# myir register map
Vendor: overlord; File version: 0.0.0
CPU: CA53 r0p0, little endian, no MPU, FPU, I-cache, D-cache, 0 interrupt priority bits
Registers are 32-bit, read-write, reset 0x0 unless marked. A register's access mark holds for its fields unless they carry their own. Offsets are from the block's base; [hi:lo] are bit positions; {n}, {i} and the like mark numbered series; 'fields as' and 'values as' point back to an identical list.

## SD0 — SDIO 0 Controller
Base 0xFF160000
Same registers: SD1 0xFF170000
0x00 REG_SDMASYSADDRLO 16-bit — Dual purpose: low SDMA address, Auto CMD23 arg.
  [15:0] SDMA_SYSADDRESS
0x02 REG_SDMASYSADDRHI 16-bit — Dual purpose: high SDMA address, Auto CMD23 arg.
  [15:0] SDMA_SYSADDRESS
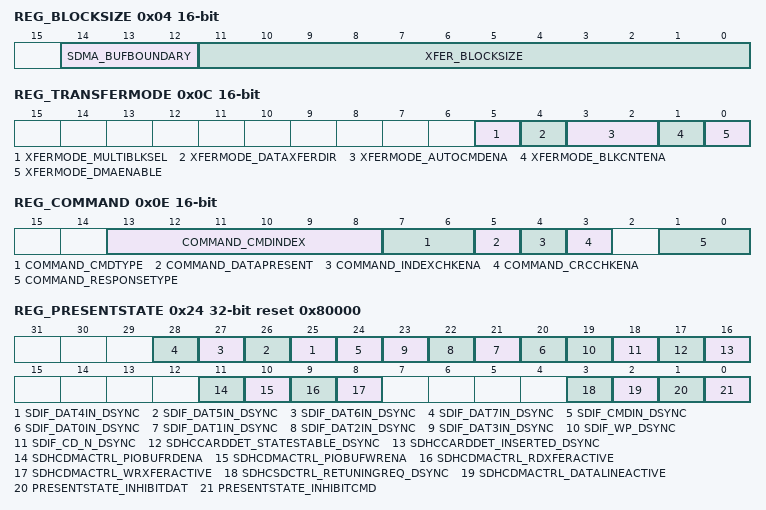
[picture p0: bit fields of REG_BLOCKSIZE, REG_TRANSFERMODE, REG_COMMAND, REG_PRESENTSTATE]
0x04 REG_BLOCKSIZE 16-bit — Configure the Number of Bytes in a Data Block.
  [14:12] SDMA_BUFBOUNDARY — The System Address register is updated at every system boundary during the DMA transfer The DMA transfer waits at the every boundary specified by these fields and the SDIO controller generates the DMA interrupt to request the controller to update the System Address register. This function is active when the [DMA Enable] bit in the Transfer Mode register is set = 1. 000b: 4KB 001b: 8KB 010b: 16KB 011b: 32KB 100b: 64KB 101b: 128KB 110b: 256KB 111b: 512KB
  [11:0] XFER_BLOCKSIZE — Read-only. Valid if no transaction is executing (i.e after a transaction has stopped). 0000h: No data transfer. 0001h: 1 byte 0002h: 2 bytes 0003h: 3 bytes .. 0200h: 512 bytes .. 0800h: 2048 bytes (maximum block size)
0x06 REG_BLOCKCOUNT 16-bit — Configure the number of data blocks
  [15:0] XFER_BLOCKCOUNT — The controller decrements the block count after each block transfer and stops transfers when the count reaches zero. 0000h: 0 blocks, transfers stop. 0001h: 1 block. 0002h: 2 blocks. .. FFFFh: 65535 blocks. This register is enabled when Block Count Enable in the Transfer Mode register is set to 1 and is valid only for multi-block transfers. Accessed the register when no transactions are executing (i.e., after a transaction has stopped). During a transfer, reads return an invalid value and writes are ignored. When saving transfer context as a result of Suspend command, the number of blocks yet to be transferred can be determined by reading this register. When restoring transfer context prior to issuing a Resume command, the Host Driver shall restore the previously save block count.
0x08 REG_ARGUMENT1LO 16-bit — Lower bits of SD Command Argument
  [15:0] COMMAND_ARGUMENT1
0x0A REG_ARGUMENT1HI 16-bit — Upper bits of SD Command Argument
  [15:0] COMMAND_ARGUMENT1
0x0C REG_TRANSFERMODE 16-bit — Control the Data Transfer Operations.
  [5] XFERMODE_MULTIBLKSEL — '0' Single Block.'1' Multiple Block.
  [4] XFERMODE_DATAXFERDIR — 0: Write from Host to Card. 1: Read from Card to Host.
  [3:2] XFERMODE_AUTOCMDENA — 00: Auto Command Disabled. 01: Auto CMD12 Enabled. 10: Auto CMD23 Enabled. 11: reserved. There are two methods to stop multiple-block read and write operation. (1) Auto CMD12 Enable: Multiple-block read and write commands for memory require CMD12 to stop the operation. The controller issues CMD12 automatically when the last block transfer is completed. Auto CMD12 error is indicated in the Auto CMD Error Status register. The driver shall not set this bit if the command does not require Auto CMD12. (2) Auto CMD23 Enable: The controller issues an Auto CMD23 before issuing a command specified in the Command Register. The following conditions are required to use the Auto CMD23. * Auto CMD23 Supported (Host Controller Version is 3.00 or later). * A memory card that supports CMD23 (SCR[33]=1). * If DMA is used, it shall be ADMA. * Only when CMD18 or CMD25 is issued. By writing the Command register, the controller issues a CMD23 first and then issues a command specified by the Command Index in Command register 32-bit block count value for CMD23 is set to SDMA System Address / Argument 2 register.
  [1] XFERMODE_BLKCNTENA — 0: disable (setting is also useful for executing an infinite transfer). 1: enable. Applicable to multiple block transfers.
  [0] XFERMODE_DMAENABLE — If this bit is set to 1, a DMA operation shall begin when the Host Driver writes to the upper byte of Command register (00Fh). 0: disable DMA. 1: enable DMA.
0x0E REG_COMMAND 16-bit — Controller Commands.
  [13:8] COMMAND_CMDINDEX — * ACMD [0:63].
  [7:6] COMMAND_CMDTYPE — Suspend Command: If the Suspend command succeeds, the controller assumes the SD I/O has been released and that it is possible to issue the next command using the SD_DAT signals. The controller de-asserts Read Wait for read transactions and stops checking busy for write transactions. The Interrupt cycle starts in 4-bit mode. If the Suspend command fails, the controller maintain its current state. and the controller shall restart the transfer by setting Continue Request in the Block Gap Control Register. Resume Command: The SDIO controller re-starts the data transfer by restoring the registers in the range of 000-00Dh. The controller checks for busy before starting write transfers. Abort Command: * If this command is set when executing a read transfer, the controller stops adding content to the receive buffer. * If this command is set when executing a write transfer, the controller stops driving the SD_DAT signals. After issuing the Abort command, the controller should issue a software reset. 00: Normal 01: Suspend 10: Resume 11: Abort
  [5] COMMAND_DATAPRESENT — If is set to 0 for the following: 1. Commands using only CMD line (ex. CMD52). 2. Commands with no data transferbut using busy signal on DAT[0]line (R1b or R5b ex. CMD38). 3. Resume Command.'0' Data not Present'1' Data present
  [4] COMMAND_INDEXCHKENA — If it is not, it is reported as a Command Index Error. If this bit is set to 0, the Index field is not checked.'0' Disable'1' Enable
  [3] COMMAND_CRCCHKENA — If an error is detected, it is reported as a Command CRC Error. If this bit is set to 0, the CRC field is not checked.'0' Disable'1' Enable
  [1:0] COMMAND_RESPONSETYPE — '00' No Response'01' Response Length 136'10' Response Length 48'11' Response Length 48 check busy after response
0x10 REG_RESPONSE0 16-bit — Response 0 from SD Card.
  [15:0] COMMAND_RESPONSE
{0x10+2i} REG_RESPONSE{i} 16-bit (i=1..7) — This register is used to store responses from SD Cards
  [15:0] COMMAND_RESPONSE
0x20 REG_DATAPORT — Read/write internal buffer.
  [31:0] SDHCDMACTRL_PIOBUFRDDATA
0x24 REG_PRESENTSTATE reset 0x80000 — SDIO Controller Status, read-only.
  [n+21] SDIF_DAT{n}IN_DSYNC (n=4..7)
  [24] SDIF_CMDIN_DSYNC
  [n+20] SDIF_DAT{n}IN_DSYNC (n=0..3) — This is especially useful in detecting the busy signal level from DAT[0].
  [19] SDIF_WP_DSYNC — This bit reflects the inversion of the SDx_WP pin. 0: Write protected, SDx_WP pin = High. 1: Write enabled, SDx_WP pin = Low.
  [18] SDIF_CD_N_DSYNC — 0: No Card present, SDx_CDn pin = High. 1: Card present, SDx_CDn pin = Low.
  [17] SDHCCARDDET_STATESTABLE_DSYNC — If it is 0, the Card Detect Pin Level is not stable. If this bit is set to 1,it means the Card Detect Pin Level is stable. The Software Reset For All in the Software Reset Register shall not affect this bit.'0' Reset of Debouncing'1' No Card or Inserted
  [16] SDHCCARDDET_INSERTED_DSYNC — Read-only. Changing from 0 to 1 generates a Card Insertion interrupt in the Normal Interrupt Status register. Changing from 1 to 0 generates a Card Removal interrupt in the Normal Interrupt Status register. The Software Reset For All in the Software Reset register does not affect this bit. If a Card is removed while its power is on and its clock is oscillating, the controller clears SD Bus Power in the Power Control register and SD Clock Enable in the Clock control register. In addition the Host Driver should clear the controller using the Software Reset For All in Software register. The card detect is active regardless of the SD Bus Power. 0: Reset or Debouncing or No Card. 1: Card Inserted.
  [11] SDHCDMACTRL_PIOBUFRDENA — This read only flag indicates that valid data exists in the host side buffer status. If this bit is 1, readable data exists in the buffer. A change of this bit from 1 to 0 occurs when all the block data is read from the buffer. A change of this bit from 0 to 1 occurs when all the block data is ready in the buffer and generates the Buffer Read Ready Interrupt.'0' Read Disable'1' Read Enable
  [10] SDHCDMACTRL_PIOBUFWRENA — Read-only. This flag indicates if space is available for writing data. 0: do not write to the register port. 1: data can be written to the buffer via the register port. A change from 1 to 0 indicates the buffer is full. A change from 0 to 1 occurs when top of block data can be written to the buffer and generates the Buffer Write Ready Interrupt.
  [9] SDHCDMACTRL_RDXFERACTIVE — Read-only. This bit is set to 1 for either of the following conditions: * After the end bit of the read command, or * When writing a 1 to continue Request in the Block Gap Control register to restart a read transfer. This bit is cleared to 0 for either of the following conditions: * When the last data block as specified by block length is transferred to the system, or * When all valid data blocks have been transferred to the system and no current block transfers are being sent as a result of the Stop At Block Gap Request set to 1. A transfer complete interrupt is generated when this bit changes to 0. 0: No valid data 1: Transferring data
  [8] SDHCDMACTRL_WRXFERACTIVE — If this bit is 0, it means no valid write data exists in the HC. This bit is set in either of the following cases: * After the end bit of the write command. * When writing a 1 to Continue Request in the Block Gap Control register to restart a write transfer. This bit is cleared in either of the following cases: * After getting the CRC status of the last data block as specified by the transfer count (Single or Multiple) * After getting a CRC status of any block where data transmission is about to be stopped by a Stop At Block Gap Request. During a write transaction, a Block Gap Event interrupt is generated when this bit is changed to 0, as a result of the Stop At Block Gap Request being set. This status is useful for the HD in determining when to issue commands during write busy.'0' No valid data'1' Transferring data
  [3] SDHCSDCTRL_RETUNINGREQ_DSYNC — Re-tune the I/O timing when the data window is shifted by temperature changes or to improve timing margins to receive correct data. 0: Sampling clock is okay (it's fixed timing or well tuned). 1: Re-tune the sampling clock. This bit is set = 0 when a command is issued by setting the Execute Tuning bit in the Host Control 2 register. When software writes this bit from a 0 to 1 and [Sampling Clock Select] = 1 (not fixed sampling), the controller triggers the re-tune event. Refer to Normal Interrupt registers for more detail.
  [2] SDHCDMACTRL_DATALINEACTIVE — 1: active.
  [1] PRESENTSTATE_INHIBITDAT — [ ] 0: controller can issue the next SD command. Commands with busy signal belong to Command Inhibit (DAT) (ex. R1b, R5b type). When the status indicator changes from a 0 to 1, the Transfer Complete interrupt asserts. Note: The SD Host Driver can save registers in the range of 000-00Dh; for a suspend transaction this bit changes from 1 to 0.'0' Can issue command which uses the DAT line'1' Cannot issue command which uses the DATline
  [0] PRESENTSTATE_INHIBITCMD — 0: The CMD line is not in use and the controller can issue a SD command using the CMD line. This bit is set immediately after the Command register (00Fh) is written. This bit is cleared when the command response is received. Even if the Command Inhibit (DAT) is set to 1, Commands using only the CMD line can be issued if this bit is 0. Changing from 1 to 0 generates a Command complete interrupt in the Normal Interrupt Status register. If the controller cannot issue the command because of a command conflict error or because of Command Not Issued By Auto CMD12 Error, this bit remains a 1 and the Command Complete interrupt is not set. Status issuing Auto CMD12 is not read from this bit. Auto CMD12 and Auto CMD23 consist of two responses. In this case, this bit is not cleared by the response of CMD12 or CMD23 but cleared by the response of a read/write command. Status issuing Auto CMD12 is not read from this bit. So if a command is issued during Auto CMD12 operation, controller issues two commands: CMD12 and a command set by Command register.
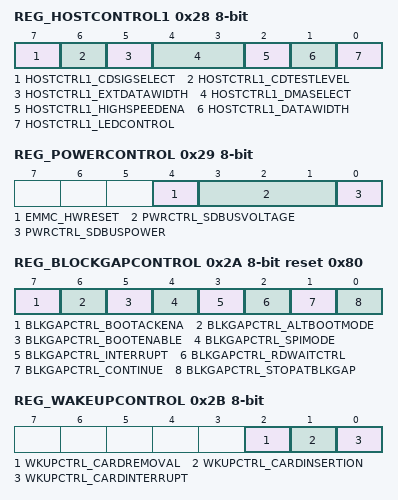
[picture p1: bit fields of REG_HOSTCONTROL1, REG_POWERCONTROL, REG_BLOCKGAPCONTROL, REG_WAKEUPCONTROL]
0x28 REG_HOSTCONTROL1 8-bit — Controller Configuration.
  [7] HOSTCTRL1_CDSIGSELECT — 0: SD_CDn is selected (for normal use) 1: The card detect test level is selected
  [6] HOSTCTRL1_CDTESTLEVEL — Generates (card ins or card removal) interrupt when the normal int sts enable bit is set.'0' No Card'1' Card Inserted
  [5] HOSTCTRL1_EXTDATAWIDTH — Support of this function is indicated in 8-bit Support for Embedded Device in the Capabilities register. If a device supports 8-bit bus mode, this bit may be set to 1. If this bit is 0, bus width is controlled by Data Transfer Width in the Host Control 1 register.This bit is not effective when multiple devices are installed on a bus slot (Slot Type is set to 10b in the Capabilities register). In this case, each device bus width is controlled by Bus Width Preset field in the Shared Bus register.'0' Bus width is selected by data transfer width'1' 8-bit bus width
  [4:3] HOSTCTRL1_DMASELECT — The host driver shall check support of DMA modes by referring the Capabilities register.'00' SDMA'01' 32 bit ADMA1 address'10' 32 bit ADMA2 address'11' 64 bit ADMA2 Address Note: Switching between 32-bit and 64-bit operation will require a reset. Write the [swreset_for_cmd] bit of SDHC register reg_software to reset.
  [2] HOSTCTRL1_HIGHSPEEDENA — Before setting this bit, the driver shall check the High Speed Support in the capabilities register. If this bit is set to 0 (default), the HC outputs CMD line and DAT lines at the falling edge of the SD clock (up to 25 MHz/20MHz for MMC). If this bit is set to 1,the HC outputs CMD line and DAT lines at the rising edge of the SD clock (up to 50 MHz for SD/52MHz for MMC)/208Mhz (for SD3.0). If Preset Value Enable in the Host Control 2 register is set to 1, Host Driver needs to reset SD Clock Enable before changing this field to avoid generating clock glitches. After setting this field, the Host Driver sets SD Clock Enable again. 0: Normal Speed Mode. 1: High Speed Mode.
  [1] HOSTCTRL1_DATAWIDTH — The driver shall select it to match the data width of the SD card. 0: 1-bit mode 1: 4-bit mode
  [0] HOSTCTRL1_LEDCONTROL — If the software is going to issue multiple SD commands, this bit can be set during all transactions. It is not necessary to change for each transaction.'0' LED Off'1' LED On
0x29 REG_POWERCONTROL 8-bit — SD Bus Power and Voltage Level.
  [4] EMMC_HWRESET
  [3:1] PWRCTRL_SDBUSVOLTAGE — Before setting this register, the HD shall check the voltage support bits in the capabilities register. If an unsupported voltage is selected, the Host System shall not supply SD bus voltage.'000'- '100' Reserved'101' 1.8V(Typ.)'110' 3.0V(Typ.)'111' 3.3V(Flattop.)
  [0] PWRCTRL_SDBUSPOWER — If the HC detects the No Card State, this bit shall be cleared.'0' Power Off'1' Power On
0x2A REG_BLOCKGAPCONTROL 8-bit reset 0x80 — This register is used to program the block gap request, read wait control and interrupt at block gap
  [7] BLKGAPCTRL_BOOTACKENA — '0' Will not wait for boot ack from eMMC card,'1' Wait for boot ack from eMMC card
  [6] BLKGAPCTRL_ALTBOOTMODE — '0' To stop alternative boot mode access,'1' To start alternative boot mode access
  [5] BLKGAPCTRL_BOOTENABLE — '0' To stop boot code access,'1' To start boot code access
  [4] BLKGAPCTRL_SPIMODE — '0' SD Mode, '1' SPI Mode
  [3] BLKGAPCTRL_INTERRUPT — Setting to 1 enables interrupt detection at the block gap for a multiple block transfer. If the SD card cannot signal an interrupt during a multiple block transfer, this bit should be set to 0. When the HD detects an SD card insertion, it shall set this bit according to the CCCR of the SDIO card.
  [2] BLKGAPCTRL_RDWAITCTRL — If the card supports read wait, set this bit to enable use of the read wait protocol to stop read data using DAT[2] line. Otherwise the HC has to stop the SD clock to hold read data, which restricts commands generation. When the HD detects an SD card insertion, it shall set this bit according to the CCCR of the SDIO card. If the card does not support read wait, this bit shall never be set to 1 otherwise DAT line conflict may occur. If this bit is set to 0, Suspend / Resume cannot be supported.'0' Disable Read-Wait Control'1' Enable Read-Wait Control
  [1] BLKGAPCTRL_CONTINUE — To cancel stop at the block gap, set Stop At block Gap Request to 0 and set this bit to restart the transfer. The HC automatically clears this bit in either of the following cases: 1) In the case of a read transaction, the DAT Line Active changes from 0 to 1 as a read transaction restarts. 2) In the case of a write transaction, the Write transfer active changes from 0 to 1 as the write transaction restarts. Therefore it is not necessary for Host driver to set this bit to 0. If Stop At Block Gap Request is set to 1, any write to this bit is ignored.'0' Ignore'1' Restart
  [0] BLKGAPCTRL_STOPATBLKGAP — Applicable for non-DMA, SDMA, and ADMA transfers. Until the transfer complete is set to 1, indicating a transfer completion the Host Driver shall leave this bit set to 1. Clearing both the Stop At Block Gap Request and Continue Request shall not cause the transaction to restart. Read Wait is used to stop the read transaction at the block gap. The controller shall honour Stop At Block Gap Request for write transfers, but for read transfers it requires that the SD card support Read Wait. Therefore the Host Driver shall not set this bit during read transfers unless the SD card supports Read Wait and has set Read Wait Control to 1. In case of write transfers in which the HD writes data to the Buffer Data Port register, the HD shall set this bit after all block data is written. If this bit is set to 1, the HD shall not write data to Buffer data port register. This bit affects Read Transfer Active, Write Transfer Active, DAT line active and Command Inhibit (DAT) in the Present State register.'0' Transfer'1' Stop
0x2B REG_WAKEUPCONTROL 8-bit — Wakeup Functionality Control.
  [2] WKUPCTRL_CARDREMOVAL — FN_WUS (Wake up Support) in CIS does not affect this bit.'0' Disable'1' Enable
  [1] WKUPCTRL_CARDINSERTION — FN_WUS (Wake up Support) in CIS does not affect this bit.'0' Disable'1' Enable
  [0] WKUPCTRL_CARDINTERRUPT — This bit can be set to 1 if FN_WUS (Wake Up Support) in CIS is set to 1.'0' Disable'1' Enable
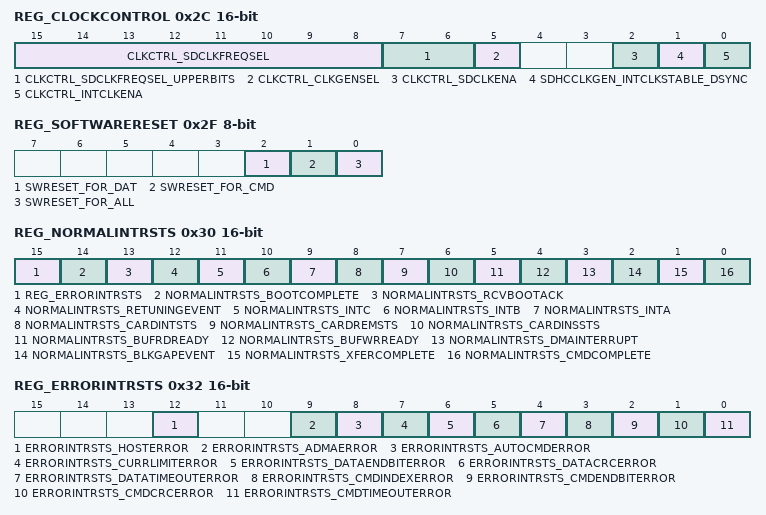
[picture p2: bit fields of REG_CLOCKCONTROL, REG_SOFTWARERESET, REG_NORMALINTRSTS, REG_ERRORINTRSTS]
0x2C REG_CLOCKCONTROL 16-bit — Clock Frequency Control and State.
  [15:8] CLKCTRL_SDCLKFREQSEL — The frequency is not programmed directly; rather this register holds the divisor of the Base Clock Frequency For SD clock in the capabilities register. Only the following settings are allowed. (1) 8-bit Divided Clock Mode 80h - base clock divided by 256 40h - base clock divided by 128 20h - base clock divided by 64 10h - base clock divided by 32 08h - base clock divided by 16 04h - base clock divided by 8 02h - base clock divided by 4 01h - base clock divided by 2 00h - base clock(10MHz-63MHz) Setting 00h specifies the highest frequency of the SD Clock. When setting multiple bits, the most significant bit is used as the divisor. But multiple bits should not be set. The two default divider values can be calculated by the frequency that is defined by the Base Clock Frequency For SD Clock in the Capabilities register. 1) 25 MHz divider value. 2) 400 KHz divider value. The frequency of the SDCLK is set by the following formula: Clock Frequency = (Baseclock) / divisor. Thus choose the smallest possible divisor which results in a clock frequency that is less than or equal to the target frequency. Maximum Frequency for SD = 50Mhz (base clock) Maximum Frequency for MMC = 52Mhz (base clock) Minimum Frequency = 195.3125Khz (50Mhz / 256), same calculation for MMC also. (2) 10-bit Divided Clock Mode Host Controller Version 3.00 supports this mandatory mode instead of the 8-bit Divided Clock Mode. The length of divider is extended to10 bits and all divider values shall be supported. 3FFh --1/2046 Divided Clock N -------1/2N Divided Clock (Duty 50%) 002h -- 1/4 Divided Clock 001h ---1/2 Divided Clock 000h --- Base Clock (10MHz-254MHz)
  [7:6] CLKCTRL_SDCLKFREQSEL_UPPERBITS
  [5] CLKCTRL_CLKGENSEL — If the Programmable Clock Mode is supported (non-zero value is set to Clock Multiplier in the Capabilities register), this bit attribute is RW, and if not supported, this bit attribute is RO and zero is read. This bit depends on the setting of Preset Value Enable in the Host Control 2 register. If the Preset Value Enable = 0, this bit is set by Host Driver. If the Preset Value Enable = 1, this bit is automatically set to a value specified in one of Preset Value registers.'0' Divided Clock Mode'1' Programmable Clock Mode
  [2] CLKCTRL_SDCLKENA — SDCLK frequency Select can be changed when this bit is 0. Then, the HC shall maintain the same clock frequency until SDCLK is stopped (Stop at SDCLK = 0). If the HC detects the No Card state, this bit shall be cleared.'0' Disable,'1' Enable
  [1] SDHCCLKGEN_INTCLKSTABLE_DSYNC — The SD Host Driver shall wait to set SD Clock Enable until this bit is set to 1. Note: This is useful when using PLL for a clock oscillator that requires setup time.'0' Not Ready,'1' Ready
  [0] CLKCTRL_INTCLKENA — The HC should stop its internal clock to go very low power state. Still, registers shall be able to be read and written. Clock starts to oscillate when this bit is set to 1. When clock oscillation is stable, the HC shall set Internal Clock Stable in this register to 1. This bit shall not affect card detection.'0' Stop,'1' Oscillate
0x2E REG_TIMEOUTCONTROL 8-bit — Set the Data Timeout Counter Value.
  [3:0] TIMEOUT_CTRVALUE — Refer to the Data Time-out Error in the Error Interrupt Status register for information on factors that dictate time-out generation. Time-out clock frequency will be generated by dividing the sdclockTMCLK by this value. When setting this register, prevent inadvertent time-out events by clearing the Data Time-out Error Status Enable (in the Error Interrupt Status Enable register). 1111 - Reserved 1110 - TMCLK * 2^27 -------------------- -------------------- 0001 - TMCLK * 2^14 0000 - TMCLK * 2^13
0x2F REG_SOFTWARERESET 8-bit — Software reset for data, command and all.
  [2] SWRESET_FOR_DAT — The following registers and bits are cleared by this bit: Buffer Data Port Register: Buffer is cleared and Initialized. Present State register: Buffer read Enable, Buffer write Enable, Read Transfer Active, Write Transfer Active, DAT Line Active, Command Inhibit (DAT). Block Gap Control register: Continue Request, Stop At Block Gap Request. Normal Interrupt Status register: Buffer Read Ready, Buffer Write Ready, Block Gap Event, Transfer Complete. 0: Operational. 1: Held in reset.
  [1] SWRESET_FOR_CMD — The following registers and bits are cleared by this bit: Present State register- Command Inhibit (CMD). Normal Interrupt Status register- Command Complete. 0: Operational. 1: Held in reset.
  [0] SWRESET_FOR_ALL — Register bits of type ROC, RW, RW1C, RWAC are cleared to 0. During its initialization, the HD shall set this bit to 1 to reset the HC. The HC shall reset this bit to 0 when capabilities registers are valid and the HD can read them. Additional use of Software Reset For All may not affect the value of the Capabilities registers. If this bit is set to 1, the SD card shall reset itself and must be re initialized by the HD. 0: Operational. 1: Held in reset.
0x30 REG_NORMALINTRSTS 16-bit — Status of all Interrupts
  [15] REG_ERRORINTRSTS — '0' No error'1' Error
  [14] NORMALINTRSTS_BOOTCOMPLETE — '0' Boot operation is not terminated'1' Boot operation is terminated
  [13] NORMALINTRSTS_RCVBOOTACK — '0' Boot ack not recieved'1' Boot ack is recieved
  [12] NORMALINTRSTS_RETUNINGEVENT — Host Controller requests Host Driver to perform re-tuning for next data transfer. Current data transfer (not large block count) can be completed without re-tuning.'0' Re-tuning not required'1' Re-tuning should be performed
  [11] NORMALINTRSTS_INTC — Writing this bit to 1 does not clear this bit. It is cleared by resetting the INT_C interrupt factor.
  [10] NORMALINTRSTS_INTB — Writing this bit to 1 does not clear this bit. It is cleared by resetting the INT_B interrupt factor.
  [9] NORMALINTRSTS_INTA — Writing this bit to 1 does not clear this bit. It is cleared by resetting the INT_A interrupt factor. NOTE: INT_A, INT_B, and INT_C are to be implemented based on the Application Requirements. By default these are not implemented as there is no specific requirement from Customers.
  [8] NORMALINTRSTS_CARDINTSTS — It is cleared by resetting the SD card interrupt factor. In 1-bit mode, the HC shall detect the Card Interrupt without SD Clock to support wakeup. In 4-bit mode, the card interrupt signal is sampled during the interrupt cycle, so there are some sample delays between the interrupt signal from the card and the interrupt to theHost system. when this status has been set and the HD needs to start this interrupt service, Card Interrupt Status Enable in the Normal Interrupt Status register shall be set to 0 in order to clear the card interrupt statuses latched in the HC and stop driving the Host System. After completion of the card interrupt service (the reset factor in the SD card and the interrupt signal may not be asserted), set Card Interrupt Status Enable to 1 and start sampling the interrupt signal again. Interrupt detected by DAT[1] is supported when there is a card per slot. In case of shared bus, interrupt pins are used to detect interrupts. If 000b is set to Interrupt Pin Select in the Shared Bus Control register, this status is effective. Non-zero value is set to Interrupt Pin Select, INT_A, INT_B or INT_C is then used to device interrupts. Card Interrupt: 0: inactive. 1: active.
  [7] NORMALINTRSTS_CARDREMSTS — When the HD writes this bit to 1 to clear this status the status of the Card Inserted in the Present State register should be confirmed. Because the card detect may possibly be changed when the HD clear this bit an Interrupt event may not be generated.'0' Card State Stable or Debouncing'1' Card Removed
  [6] NORMALINTRSTS_CARDINSSTS — When the HD writes this bit to 1 to clear this status the status of the Card Inserted in the Present State register should be confirmed. Because the card detect may possibly be changed when the HD clear this bit an Interrupt event may not be generated.'0' Card State Stable or Debouncing'1' Card Inserted
  [5] NORMALINTRSTS_BUFRDREADY — '0' Not ready to read buffer,'1' Ready to read buffer
  [4] NORMALINTRSTS_BUFWRREADY — '0' Not ready to write to buffer, '1' Ready to write to buffer
  [3] NORMALINTRSTS_DMAINTERRUPT — '0' No DMA Interrupt'1' DMA Interrupt is generated
  [2] NORMALINTRSTS_BLKGAPEVENT — Read Transaction: This bit is set at the falling edge of the DAT Line Active Status (When the transaction is stopped at SD Bus timing. The Read Wait must be supported inorder to use this function). Write Transaction: This bit is set at the falling edge of Write Transfer Active Status (After getting CRC status at SD Bus timing).'0' No Block Gap Event'1' Transaction stopped at Block Gap
  [1] NORMALINTRSTS_XFERCOMPLETE — Read Transaction: This bit is set at the falling edge of Read Transfer Active Status. There are two cases in which the Interrupt is generated. The first is when a data transfer is completed as specified by data length (After the last data has been read to the Host Sys- tem). The second is when data has stopped at the block gap and completed the data transfer by setting the Stop At Block Gap Request in the Block Gap Control Register (After valid data has been read to the Host System). Write Transaction: This bit is set at the falling edge of the DAT Line Active Status. There are two cases in which the Interrupt is generated. The first is when the last data is written to the card as specified by data length and Busy signal is released. The second is when data transfers are stopped at the block gap by setting Stop At Block Gap Request in the Block Gap Control Register and data transfers completed. (After valid data is written to the SD card and the busy signal is released). Note: Transfer Complete has higher priority than Data Time-out Error. If both bits are set to 1, the data transfer can be considered complete. Note: While performing tuning procedure (Execute Tuning is set to 1), Transfer Complete is not set to 1'0' No Data Transfer Complete,'1' Data Transfer Complete
  [0] NORMALINTRSTS_CMDCOMPLETE — If both are set to 1, it can be considered that the response was not received correctly.'0' No Command Complete,'1' Command Complete
0x32 REG_ERRORINTRSTS 16-bit — Error Interrupts Status
  [12] ERRORINTRSTS_HOSTERROR
  [9] ERRORINTRSTS_ADMAERROR — The state of the ADMA at an error occurrence is saved in the ADMA Error Status Register.'0' No error'1' Error
  [8] ERRORINTRSTS_AUTOCMDERROR — This bit is set when detecting that one of the bits D00-D04 in Auto CMD Error Status register has changed from 0 to 1. In case of Auto CMD12, this bit is set to 1, not only when the errors in Auto CMD12 occur but also when Auto CMD12 is not executed due to the previous command error.'0' No error'1' Error
  [7] ERRORINTRSTS_CURRLIMITERROR — If the HC supports the Current Limit Function, it can be protected from an Illegal card by stopping power supply to the card in which case this bit indicates a failure status. Reading 1 means the HC is not supplying power to SD card due to some failure. Reading 0 means that the HC is supplying power and no error has occurred. This bit shall always set to be 0, if the HC does not support this function.'0' No error'1' Power Fail Note: The current_Limit_Error is to be implemented if customer application requires it. By default it is not implemented as there is no specific requirement from Customers.
  [6] ERRORINTRSTS_DATAENDBITERROR
  [5] ERRORINTRSTS_DATACRCERROR — '0' No error'1' Error
  [4] ERRORINTRSTS_DATATIMEOUTERROR — Busy Timeout for R1b, R5b type. 2. Busy Timeout after Write CRC status 3. Write CRC status Timeout 4. Read Data Timeout.'0' No Error'1' Timeout
  [3] ERRORINTRSTS_CMDINDEXERROR — '0' No Error'1' Error
  [2] ERRORINTRSTS_CMDENDBITERROR — '0' No Error, '1' End bit error generated
  [1] ERRORINTRSTS_CMDCRCERROR — 1. If a response is returned and the Command Time-out Error is set to 0, this bit is set to 1 when detecting a CRT error in the command response 2. The HC detects a CMD line conflict by monitoring the CMD line when a command is issued. If the HC drives the CMD line to 1 level, but detects 0 level on the CMD line at the next SDCLK edge, then the HC shall abort the command (Stop driving CMD line) and set this bit to 1. The Command Timeout Error shall also be set to 1 to distinguish CMD line conflict.'0' No Error,'1' CRC Error
  [0] ERRORINTRSTS_CMDTIMEOUTERROR — If the HC detects a CMD line conflict, in which case Command CRC Error shall also be set. This bit shall be set without waiting for 64 SDCLK cycles because the command will be aborted by the HC.'0' Error'1' Timeout
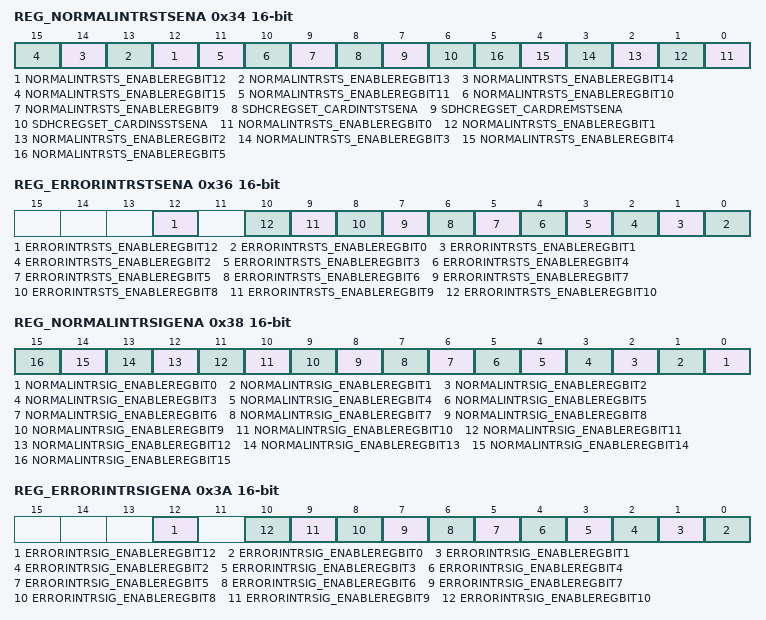
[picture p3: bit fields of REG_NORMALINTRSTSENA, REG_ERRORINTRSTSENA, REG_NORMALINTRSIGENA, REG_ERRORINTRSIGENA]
0x34 REG_NORMALINTRSTSENA 16-bit — Normal-type Interrupts Status Enables.
  [n] NORMALINTRSTS_ENABLEREGBIT{n} (n=12..15)
  [11] NORMALINTRSTS_ENABLEREGBIT11 — The Host Driver may clear this bit before servicing the INT_C and may set this bit again after all interrupt requests to INT_C pin are cleared to prevent inadvertent interrupts.
  [10] NORMALINTRSTS_ENABLEREGBIT10 — The Host Driver may clear this bit before servicing the INT_B and may set this bit again after all interrupt requests to INT_B pin are cleared to prevent inadvertent interrupts.
  [9] NORMALINTRSTS_ENABLEREGBIT9 — The Host Driver may clear this bit before servicing the INT_A and may set this bit again after all interrupt requests to INT_A pin are cleared to prevent inadvertent interrupts.
  [8] SDHCREGSET_CARDINTSTSENA — The Card Interruptdetection is stopped when this bit is cleared and restarted when this bit is set to 1. The HD may clear the Card Interrupt Status Enable before servicing the Card Interrupt and may set this bit again after all Interrupt requests from the card are cleared to prevent inadvertent Interrupts.
  [7] SDHCREGSET_CARDREMSTSENA
  [6] SDHCREGSET_CARDINSSTSENA
  [n] NORMALINTRSTS_ENABLEREGBIT{n} (n=0..5)
0x36 REG_ERRORINTRSTSENA 16-bit — Error-type Interrupts Status Enables.
  [12] ERRORINTRSTS_ENABLEREGBIT12, [n] ERRORINTRSTS_ENABLEREGBIT{n} (n=0..10)
0x38 REG_NORMALINTRSIGENA 16-bit — Normal-type Interrupts Signal Enables.
  [n] NORMALINTRSIG_ENABLEREGBIT{n} (n=0..15)
0x3A REG_ERRORINTRSIGENA 16-bit — Error-type Interrupts Signal Enables.
  [12] ERRORINTRSIG_ENABLEREGBIT12, [n] ERRORINTRSIG_ENABLEREGBIT{n} (n=0..10)
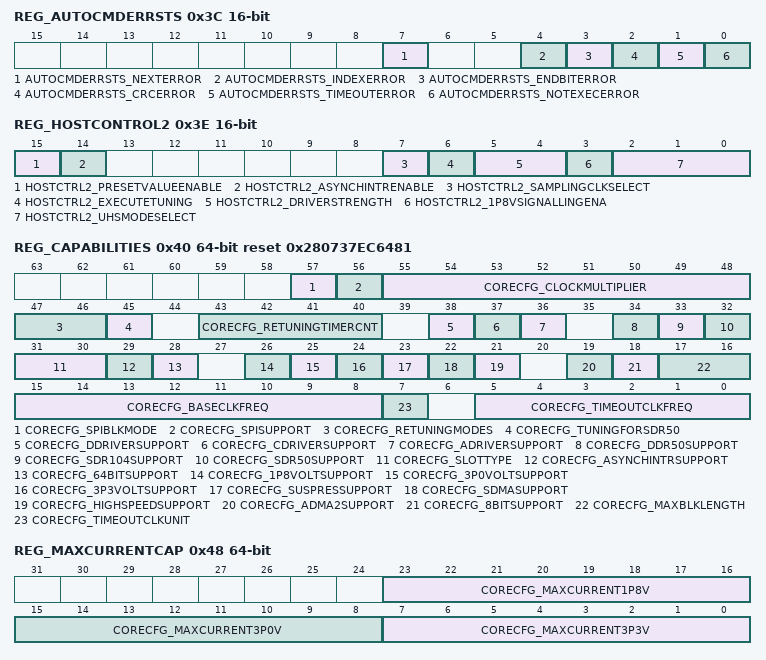
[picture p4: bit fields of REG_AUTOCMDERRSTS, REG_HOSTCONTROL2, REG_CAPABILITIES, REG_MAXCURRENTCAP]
0x3C REG_AUTOCMDERRSTS 16-bit — CMD12 response error of Auto CMD12 and CMD23.
  [7] AUTOCMDERRSTS_NEXTERROR — This bit is set to 0 when Auto CMD Error is generated by Auto CMD23.'0' No Error'1' Not Issued
  [4] AUTOCMDERRSTS_INDEXERROR — '0' No Error,'1' Error.
  [3] AUTOCMDERRSTS_ENDBITERROR — '0' No Error,'1' End Bit Error Generated
  [2] AUTOCMDERRSTS_CRCERROR — '0' No error'1' CRC Error Generated
  [1] AUTOCMDERRSTS_TIMEOUTERROR — If this bit is set to 1, the other error status bits (D04 - D02) are meaningless.'0' No error'1' Timeout
  [0] AUTOCMDERRSTS_NOTEXECERROR — Setting this bit to 1 means the HC cannot issue Auto CMD12 to stop memory multiple block transfer due to some error. If this bit is set to 1, other error status bits (D04 - D01) are meaningless. This bit is set to 0 when Auto CMD Error is generated by Auto CMD23'0' Executed, '1' Not Executed
0x3E REG_HOSTCONTROL2 16-bit — UHS Mode, I/O Drive, Tuning, Clocking, Intr, and Presets.
  [15] HOSTCTRL2_PRESETVALUEENABLE — 00 supports this bit. As the operating SDCLK frequency and I/O driver strength depend on the Host System implementation, it is difficult to determine these parameters in the Standard Host Driver. When Preset Value Enable is set to automatic. This bit enables the functions defined in the Preset Value registers.'0' SDCLK and Driver Strength are controlled by Host Driver.'1' Automatic Selection by Preset Value are Enabled. If this bit is set to 0, SDCLK Frequency Select, Clock Generator Select in the Clock Control register and Driver Strength Select in Host Control 2 register are set by Host Driver. If this bit is set to 1, SDCLK Frequency Select, Clock Generator Select in the Clock Control register and Driver Strength Select in Host Control 2 register are set by Host Controller as specified in the Preset Value registers.
  [14] HOSTCTRL2_ASYNCHINTRENABLE — Asynchronous interrupt is effective when DAT[1] interrupt is used in 4-bit SD mode (and zero is set to Interrupt Pin Select in the Shared Bus Control register). If this bit is set to 1, the Host Driver can stop the SDCLK during asynchronous interrupt period to save power. During this period, the Host Controller continues to deliver Card Interrupt to the host when it is asserted by the Card.'0' Disabled'1' Enabled
  [7] HOSTCTRL2_SAMPLINGCLKSELECT — Writing 1 to this bit is meaningless and ignored. Setting 1 means that tuning is completed successfully and setting 0 means that tuning is failed. Host Controller uses this bit to select sampling clock to receive CMD and DAT. This bit is cleared by writing 0. Change of this bit is not allowed while the Host Controller is receiving response or a read data block.'0' Fixed clock is used to sample data'1' Tuned clock is used to sample data
  [6] HOSTCTRL2_EXECUTETUNING — The result of tuning is indicated to Sampling Clock Select. Tuning procedure is aborted by writing 0 for more detail about tuning procedure.'0' Not Tuned or Tuning Completed'1' Execute Tuning
  [5:4] HOSTCTRL2_DRIVERSTRENGTH — 8V signaling. In 3.3V signaling, this field is not effective. This field can be set to driver type A, B, C, or D. This bit depends on setting of Preset Value Enable: If Preset Value Enable = 0, this field is set by Host Driver. If Preset Value Enable = 1, this field is automatically set by the hardware to a value specified in the selected Preset Value register. 00: Driver Type B (default) 01: Driver Type A 10: Driver Type C 11: Driver Type D
  [3] HOSTCTRL2_1P8VSIGNALLINGENA — 3.3V is supplied to the card regardless of signaling voltage. Setting this bit from 0 to 1 starts changing signal voltage from 3.3V to 1.8V. 1.8V regulator output shall be stable within 5ms. Host Controller clears this bit if switching to 1.8V signaling fails. Clearing this bit from 1 to 0 starts changing signal voltage from 1.8V to 3.3V. 3.3V regulator output shall be stable within 5ms. Host Driver can set this bit to 1 when Host Controller supports 1.8V signaling (One of support bits is set to 1: SDR50, SDR104 or DDR50 in the Capabilities register) and the card or device supports UHS-I.'0' 3.3V Signalling, '1' 1.8V Signalling
  [2:0] HOSTCTRL2_UHSMODESELECT — 8V Signaling Enable is set to 1.If Preset Value Enable in the Host Control 2 register is set to 1, Host Controller sets SDCLK Frequency Select, Clock Generator Select in the Clock Control register and Driver Strength Select according to Preset Value registers. In this case, one of preset value registers is selected by this field. Host Driver needs to reset SD Clock Enable before changing this field to avoid generating clock glitch. After setting this field, Host Driver sets SD Clock Enable again. 000: SDR12 001: SDR25 010: SDR50 011: SDR104 100: DDR50 101 - 111: Reserved. When SDR50, SDR104 or DDR50 is selected for SDIO card, interrupt detection at the block gap shall not be used. Read Wait timing is changed for these modes. Refer to the SDIO Specification Version 3.00 for more detail.
0x40 REG_CAPABILITIES 64-bit reset 0x280737EC6481 (reset mask 0xFFFFFFFF) — Host controller implementation.
  [57] CORECFG_SPIBLKMODE
  [56] CORECFG_SPISUPPORT
  [55:48] CORECFG_CLOCKMULTIPLIER
  [47:46] CORECFG_RETUNINGMODES — 00: Mode 1 01: Mode 2 10: Mode 3 11: reserved. There are two re-tuning timings:Re-Tuning Request and expiration of a Re-Tuning Timer. By receiving either timing, the Host Driver executes the re-tuning procedure just before a next command issue.
  [45] CORECFG_TUNINGFORSDR50
  [43:40] CORECFG_RETUNINGTIMERCNT — 0h: Get information via other source 1h: 1 seconds 2h: 2 seconds 3h: 4 seconds 4h: 8 seconds ------ nh: 2 (n-1) seconds ------ Bh: 1024 seconds Others: reserved
  [38] CORECFG_DDRIVERSUPPORT — 8 Signaling) is not supported.
  [37] CORECFG_CDRIVERSUPPORT — 8 Signaling) is not supported.
  [36] CORECFG_ADRIVERSUPPORT — 8 Signaling) is not supported.
  [34] CORECFG_DDR50SUPPORT
  [33] CORECFG_SDR104SUPPORT
  [32] CORECFG_SDR50SUPPORT
  [31:30] CORECFG_SLOTTYPE — (A host controller register set is defined perslot.) Embedded slot for one device (01b) means that only one non-removable device is connected to a SD bus slot. Shared Bus Slot (10b) can be set if Host Controller supports Shared Bus Control register. The Standard Host Driver controls only a removable card or one embedded device is connected to a SD bus slot. If a slot is configured for shared bus (10b), the Standard Host Driver does not control embedded devices connected to a shared bus. Shared bus slot is controlled by a specific host driver developed by a Host System.'00' Removable Card Slot'01' Embedded Slot for One Device'10' Shared Bus Slot'11' Reserved
  [29] CORECFG_ASYNCHINTRSUPPORT — 00.
  [28] CORECFG_64BITSUPPORT
  [26] CORECFG_1P8VOLTSUPPORT — 8V I/O.
  [25] CORECFG_3P0VOLTSUPPORT — 0V I/O.
  [24] CORECFG_3P3VOLTSUPPORT — 3V I/O.
  [23] CORECFG_SUSPRESSUPPORT
  [22] CORECFG_SDMASUPPORT
  [21] CORECFG_HIGHSPEEDSUPPORT — '0' High Speed Not Supported'1' High Speed Supported
  [19] CORECFG_ADMA2SUPPORT
  [18] CORECFG_8BITSUPPORT — This bit is not effective when Slot Type is set to 10b. In this case, refer to Bus Width Preset in the Shared Bus resister.'0' Extended Media Bus Not Supported'1' Extended Media Bus Supported
  [17:16] CORECFG_MAXBLKLENGTH — The buffer shall transfer this block size without wait cycles. Three sizes can be defined as indicated below.'00' 512byte'01' 1024byte'10' 2048byte'11' 4096byte
  [15:8] CORECFG_BASECLKFREQ — 00 and 2.00. Upper 2-bit is not effective and always 0. Unit values are 1MHz. The supported clock range is 10MHz to 63MHz. 11xx xxxxb' Not Supported'0011 1111b' 63MHz'0000 0010b' 2MHz'0000 0001b' 1MHz'0000 0000b'Get Information via another method (2)8-bit Base Clock Frequency: This mode is supported by the Host Controller Version 3.00.Unit values are 1MHz. The supported clock range is 10MHz to 255MHz.'FFh' 255MHz'02h' 2MHz'01h' 1MHz'00h' Get Information via another method. If the real frequency is 16.5MHz, the lager value shall be set 0001 0001b (17MHz) because the Host Driver use this value to calculate the clock divider value (Refer to the SDCLK Frequency Select in the Clock Control register.) and it shall not exceed upper limit of the SD Clock frequency. If these bits are all 0, the Host System has to get information via another method.
  [7] CORECFG_TIMEOUTCLKUNIT
  [5:0] CORECFG_TIMEOUTCLKFREQ
0x48 REG_MAXCURRENTCAP 64-bit — Maximum current capability for each voltage.
  [23:16] CORECFG_MAXCURRENT1P8V — SD_MAXCUR1P8 register.
  [15:8] CORECFG_MAXCURRENT3P0V — SD_MAXCUR3P0 register.
  [7:0] CORECFG_MAXCURRENT3P3V — SD_MAXCUR3P3 register.
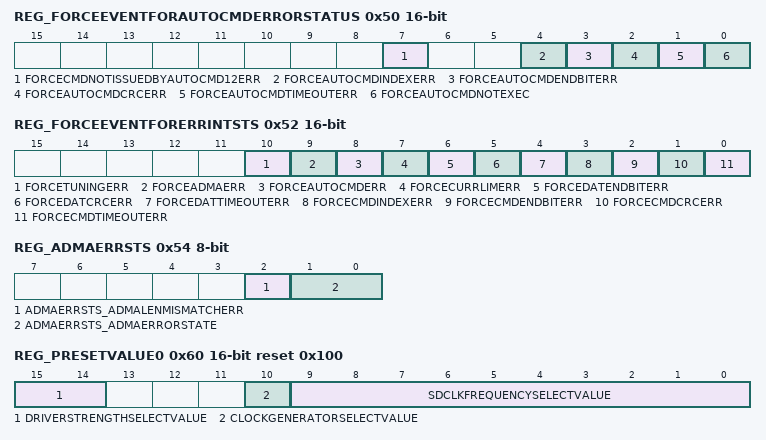
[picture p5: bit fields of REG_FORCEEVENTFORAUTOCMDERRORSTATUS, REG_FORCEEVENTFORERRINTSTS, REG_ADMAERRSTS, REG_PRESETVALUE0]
0x50 REG_FORCEEVENTFORAUTOCMDERRORSTATUS 16-bit — Generate Auto CMD Error Status Interrupts, write-only.
  [7] FORCECMDNOTISSUEDBYAUTOCMD12ERR, [4] FORCEAUTOCMDINDEXERR, [3] FORCEAUTOCMDENDBITERR, [2] FORCEAUTOCMDCRCERR, [1] FORCEAUTOCMDTIMEOUTERR, [0] FORCEAUTOCMDNOTEXEC
0x52 REG_FORCEEVENTFORERRINTSTS 16-bit — Generate Error Interrupt Status Interrupts.
  [10] FORCETUNINGERR, [9] FORCEADMAERR, [8] FORCEAUTOCMDERR, [7] FORCECURRLIMERR, [6] FORCEDATENDBITERR, [5] FORCEDATCRCERR, [4] FORCEDATTIMEOUTERR, [3] FORCECMDINDEXERR, [2] FORCECMDENDBITERR, [1] FORCECMDCRCERR, [0] FORCECMDTIMEOUTERR
0x54 REG_ADMAERRSTS 8-bit — SDIO ADMA Error State and Address.
  [2] ADMAERRSTS_ADMALENMISMATCHERR — 1) While the Block Count Enable being set, the total data length specified by the Descriptor table is different from that specified by the Block Count and Block Length. 2) Total data length can not be divided evenly by the block length. 1: Error 0: No Error
  [1:0] ADMAERRSTS_ADMAERRORSTATE — D01 - D00: ADMA Error State when error occurred Contents of SYS_SDR register. 00: ST_STOP (Stop DMA) Points to next of the error descriptor. 01: ST_FDS (Fetch Descriptor)Points to the error descriptor. 10: reserved (ADMA never stops in this state). 11: ST_TFR (Transfer Data) Points to the next error descriptor.
0x58 REG_ADMASYSADDR0 16-bit — Lower physical address for ADMA data transfer.
  [15:0] ADMA_SYSADDRESS0
0x5A REG_ADMASYSADDR1 16-bit — ADMA Physical Address, 16 LSBs.
  [15:0] ADMA_SYSADDRESS1
0x5C REG_ADMASYSADDR2 16-bit — ADMA Physical Address, 16 bits.
  [15:0] ADMA_SYSADDRESS2
0x5E REG_ADMASYSADDR3 16-bit — ADMA Physical Address, 16 MSBs.
  [15:0] ADMA_SYSADDRESS3
0x60 REG_PRESETVALUE0 16-bit reset 0x100 — This register is used to read the SDCLK Frequency Select Value,Clock Generator Select Value,Driver Strength Select Value
  [15:14] DRIVERSTRENGTHSELECTVALUE — 8V signaling bus speed modes. This field is meaningless for 3.3V signaling.'00' Driver Type B is Selected'01' Driver Type A is Selected'10' Driver Type C is Selected'11' Driver Type D is Selected
  [10] CLOCKGENERATORSELECTVALUE — 00 Compatible Clock Generator'1' Programmable Clock Generator
  [9:0] SDCLKFREQUENCYSELECTVALUE
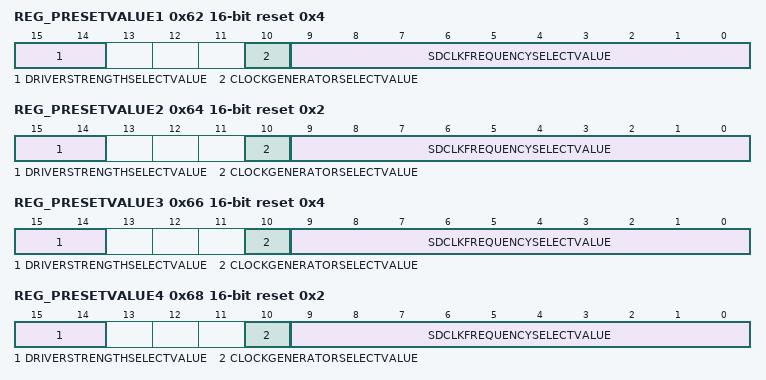
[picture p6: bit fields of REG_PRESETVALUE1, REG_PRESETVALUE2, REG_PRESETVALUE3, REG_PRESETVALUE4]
0x62 REG_PRESETVALUE1 16-bit reset 0x4 — Default Clock and I/O Drive Preset Values. Read clock select values and I/O drive.
  [15:14] DRIVERSTRENGTHSELECTVALUE — 8V signaling bus speed modes. 00: Driver Type B is selected. (default) 01: Driver Type A is selected. 10: Driver Type C is selected. 11: Driver Type D is selected. This field is meaningless for 3.3V signaling.
  [10] CLOCKGENERATORSELECTVALUE — 0: Host Controller Ver2.00 Clock Model. 1: Programmable Clock Generator.
  [9:0] SDCLKFREQUENCYSELECTVALUE
0x64 REG_PRESETVALUE2 16-bit reset 0x2 — High-Speed Clock and I/O Drive Preset Values. Read clock select values and I/O drive.
  fields as REG_PRESETVALUE0
0x66 REG_PRESETVALUE3 16-bit reset 0x4 — SDR12 Clock and I/O Drive Preset Values.
  fields as REG_PRESETVALUE0
0x68 REG_PRESETVALUE4 16-bit reset 0x2 — SDR25 Clock and I/O Drive Preset Values.
  fields as REG_PRESETVALUE0
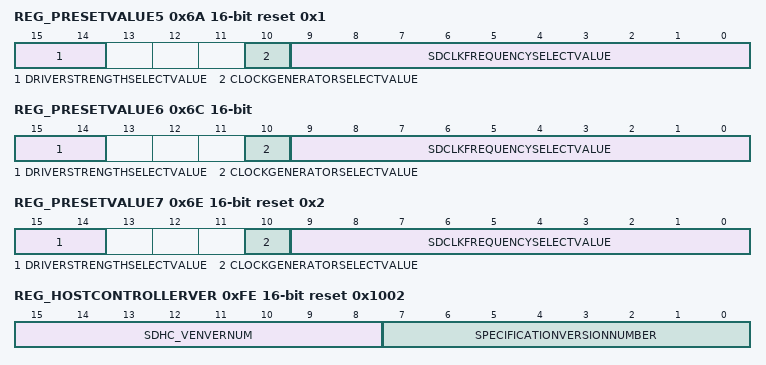
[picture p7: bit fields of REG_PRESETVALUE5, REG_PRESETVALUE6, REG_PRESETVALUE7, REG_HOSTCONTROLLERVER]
0x6A REG_PRESETVALUE5 16-bit reset 0x1 — SDR50 Clock and I/O Drive Preset Values.
  fields as REG_PRESETVALUE0
0x6C REG_PRESETVALUE6 16-bit — SDR 104 Mode Clock and I/O Drive Preset Values.
  fields as REG_PRESETVALUE0
0x6E REG_PRESETVALUE7 16-bit reset 0x2 — DDR50 Clock and I/O Drive Preset Values.
  fields as REG_PRESETVALUE0
0x70 REG_BOOTTIMEOUTCNT — Program the boot timeout value counter.
  [31:0] BOOT_TIMEOUTCNT — The value is in number of SD_CLK clocks.
0xFC REG_SLOTINTRSTS 16-bit — Read the interrupt signal for each slot.
  [7:0] SDHCHOSTIF_SLOTINTRSTS — A maximum of 8 slots can be defined.
0xFE REG_HOSTCONTROLLERVER 16-bit reset 0x1002 — Controller version and specification numbers.
  [15:8] SDHC_VENVERNUM — 0).
  [7:0] SPECIFICATIONVERSIONNUMBER — 00.
